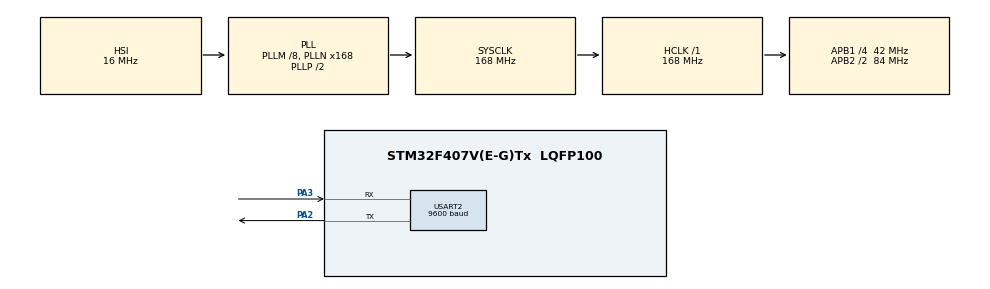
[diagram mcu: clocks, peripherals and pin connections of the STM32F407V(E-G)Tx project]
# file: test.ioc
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Mcu.Family=STM32F4
RCC.CortexFreq_Value=168000000
RCC.APB1CLKDivider=RCC_HCLK_DIV4
NVIC.USART2_IRQn=true\:0\:0\:false\:false\:true\:true\:true
USART2.BaudRate=9600
RCC.SYSCLKSource=RCC_SYSCLKSOURCE_PLLCLK
ProjectManager.StackSize=0x400
PA13.Signal=SYS_JTMS-SWDIO
PA3.Mode=Asynchronous
ProjectManager.TargetToolchain=STM32CubeIDE
RCC.HCLKFreq_Value=168000000
RCC.APB2TimFreq_Value=168000000
RCC.LSE_VALUE=32768
RCC.AHBFreq_Value=168000000
RCC.HSE_VALUE=25000000
PB3.Mode=Trace_Asynchronous_SW
board=custom
RCC.VCOOutputFreq_Value=336000000
RCC.APB2Freq_Value=84000000
PA14.Mode=Trace_Asynchronous_SW
PA13.Mode=Trace_Asynchronous_SW
Mcu.Name=STM32F407V(E-G)Tx
PA2.Signal=USART2_TX
RCC.48MHZClocksFreq_Value=84000000
PB3.Signal=SYS_JTDO-SWO
RCC.SYSCLKFreq_VALUE=168000000
Mcu.Package=LQFP100
USART2.VirtualMode=VM_ASYNC
PA14.Signal=SYS_JTCK-SWCLK
ProjectManager.HeapSize=0x200
RCC.HSI_VALUE=16000000
NVIC.PriorityGroup=NVIC_PRIORITYGROUP_4
RCC.APB2CLKDivider=RCC_HCLK_DIV2
RCC.PLLM=8
RCC.PLLN=168
RCC.APB1TimFreq_Value=84000000
PA2.Mode=Asynchronous
RCC.APB1Freq_Value=42000000
PA3.Signal=USART2_RX

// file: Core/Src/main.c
/* USER CODE BEGIN Header */
/**
  ******************************************************************************
  * @file           : main.c
  * @brief          : Main program body
  ******************************************************************************
  * @attention
  *
  * <h2><center>&copy; Copyright (c) 2021 STMicroelectronics.
  * All rights reserved.</center></h2>
  *
  * This software component is licensed by ST under BSD 3-Clause license,
  * the "License"; You may not use this file except in compliance with the
  * License. You may obtain a copy of the License at:
  *                        opensource.org/licenses/BSD-3-Clause
  *
  ******************************************************************************
  */
/* USER CODE END Header */
#include "main.h"

/* USER CODE BEGIN Includes */
#include <stdio.h>
#include <stdlib.h>
#include <string.h>
/* USER CODE END Includes */

/* USER CODE BEGIN PD */
#define BUFFER_SIZE 10
/* USER CODE END PD */

UART_HandleTypeDef huart2;

void SystemClock_Config(void);
static void MX_GPIO_Init(void);
static void MX_USART2_UART_Init(void);

/* USER CODE BEGIN 0 */
int _write(int file, char *ptr, int len)
 {
	 int DataIdx;
	 for (DataIdx = 0; DataIdx < len; DataIdx++)
	 {
		 ITM_SendChar(*ptr++);
	 }
	 return len;
 }

uint8_t rx_buffer[BUFFER_SIZE] = {0};
uint8_t tx_buffer[BUFFER_SIZE] = {0};

int reset_buffer = 0, tx_flag = 0;

void HAL_UART_RxCpltCallback(UART_HandleTypeDef* huart) {
	if (huart == &huart2) {
		printf("RxCpltCallback\n");
		memcpy(tx_buffer, rx_buffer, BUFFER_SIZE);
		tx_flag = 1;
		HAL_UART_Receive_IT(&huart2, rx_buffer, BUFFER_SIZE); // restart the interrupt reception mode
	}
	//__NOP();
}

void HAL_UART_TxCpltCallback(UART_HandleTypeDef* huart) {
	if (huart == &huart2) {
		printf("TxCpltCallback\n");
		tx_flag = 0;
		memset(tx_buffer, 0, BUFFER_SIZE);
	}
	//__NOP();
}
/* USER CODE END 0 */

int main(void)
{

  /* MCU Configuration--------------------------------------------------------*/

  /* Reset of all peripherals, Initializes the Flash interface and the Systick. */
  HAL_Init();

  /* Configure the system clock */
  SystemClock_Config();

  /* Initialize all configured peripherals */
  MX_GPIO_Init();
  MX_USART2_UART_Init();
  /* USER CODE BEGIN 2 */

  HAL_UART_Receive_IT(&huart2, rx_buffer, BUFFER_SIZE);

  //__HAL_UART_ENABLE_IT(&huart2, UART_IT_TC); // Activate flag receptie
  //__HAL_UART_ENABLE_IT(&huart2, UART_IT_RXNE); // Activate flag Tx_IT

  /* USER CODE END 2 */

  /* Infinite loop */
  /* USER CODE BEGIN WHILE */
  while (1)
  {
	printf("rx_buffer = %s\n", rx_buffer);
	printf("tx_buffer = %s\n", tx_buffer);
	if (tx_flag) {
		HAL_UART_Transmit_IT(&huart2, tx_buffer, BUFFER_SIZE);
		// HAL_Delay(100);
	}

	HAL_Delay(1000);

    /* USER CODE END WHILE */

  }
}

void SystemClock_Config(void)
{
  RCC_OscInitTypeDef RCC_OscInitStruct = {0};
  RCC_ClkInitTypeDef RCC_ClkInitStruct = {0};

  /** Configure the main internal regulator output voltage
  */
  __HAL_RCC_PWR_CLK_ENABLE();
  __HAL_PWR_VOLTAGESCALING_CONFIG(PWR_REGULATOR_VOLTAGE_SCALE1);
  /** Initializes the RCC Oscillators according to the specified parameters
  * in the RCC_OscInitTypeDef structure.
  */
  RCC_OscInitStruct.OscillatorType = RCC_OSCILLATORTYPE_HSI;
  RCC_OscInitStruct.HSIState = RCC_HSI_ON;
  RCC_OscInitStruct.HSICalibrationValue = RCC_HSICALIBRATION_DEFAULT;
  RCC_OscInitStruct.PLL.PLLState = RCC_PLL_ON;
  RCC_OscInitStruct.PLL.PLLSource = RCC_PLLSOURCE_HSI;
  RCC_OscInitStruct.PLL.PLLM = 8;
  RCC_OscInitStruct.PLL.PLLN = 168;
  RCC_OscInitStruct.PLL.PLLP = RCC_PLLP_DIV2;
  RCC_OscInitStruct.PLL.PLLQ = 4;
  if (HAL_RCC_OscConfig(&RCC_OscInitStruct) != HAL_OK)
  {
    Error_Handler();
  }
  /** Initializes the CPU, AHB and APB buses clocks
  */
  RCC_ClkInitStruct.ClockType = RCC_CLOCKTYPE_HCLK|RCC_CLOCKTYPE_SYSCLK
                              |RCC_CLOCKTYPE_PCLK1|RCC_CLOCKTYPE_PCLK2;
  RCC_ClkInitStruct.SYSCLKSource = RCC_SYSCLKSOURCE_PLLCLK;
  RCC_ClkInitStruct.AHBCLKDivider = RCC_SYSCLK_DIV1;
  RCC_ClkInitStruct.APB1CLKDivider = RCC_HCLK_DIV4;
  RCC_ClkInitStruct.APB2CLKDivider = RCC_HCLK_DIV2;

  if (HAL_RCC_ClockConfig(&RCC_ClkInitStruct, FLASH_LATENCY_5) != HAL_OK)
  {
    Error_Handler();
  }
}

static void MX_USART2_UART_Init(void)
{

  huart2.Instance = USART2;
  huart2.Init.BaudRate = 9600;
  huart2.Init.WordLength = UART_WORDLENGTH_8B;
  huart2.Init.StopBits = UART_STOPBITS_1;
  huart2.Init.Parity = UART_PARITY_NONE;
  huart2.Init.Mode = UART_MODE_TX_RX;
  huart2.Init.HwFlowCtl = UART_HWCONTROL_NONE;
  huart2.Init.OverSampling = UART_OVERSAMPLING_16;
  if (HAL_UART_Init(&huart2) != HAL_OK)
  {
    Error_Handler();
  }

}

static void MX_GPIO_Init(void)
{

  /* GPIO Ports Clock Enable */
  __HAL_RCC_GPIOA_CLK_ENABLE();
  __HAL_RCC_GPIOB_CLK_ENABLE();

}

void Error_Handler(void)
{
  __disable_irq();
  while (1)
  {
  }
}

/************************ (C) COPYRIGHT STMicroelectronics *****END OF FILE****/
